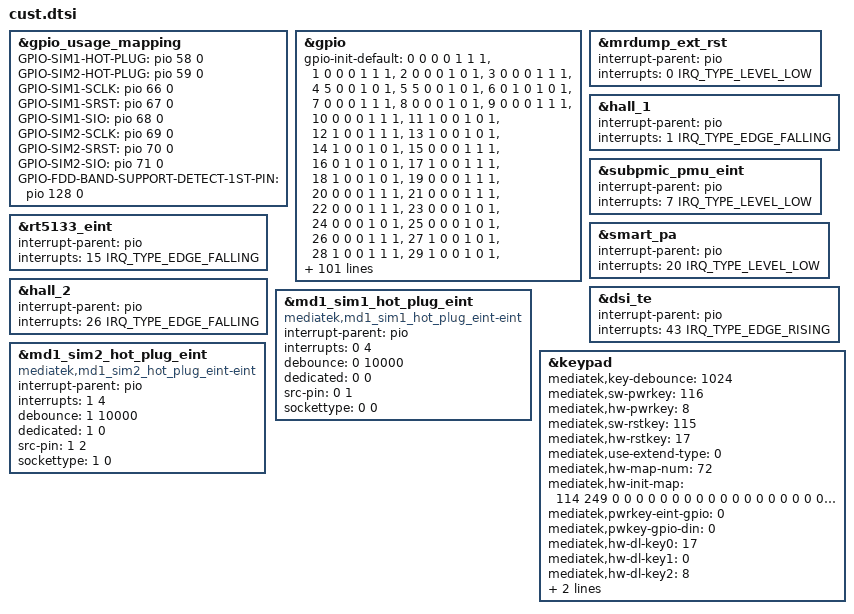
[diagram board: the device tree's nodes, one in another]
/*
 * Generated by MTK SP DrvGen Version: 3.5.160809 for MT6897.
 * 2026-04-27 19:14:05
 * Do Not Modify The File.
 * Copyright Mediatek Inc. (c) 2016.
*/

/*************************
 * ADC DTSI File
*************************/



/*************************
 * CLK_BUF DTSI File
*************************/



/*************************
 * I2C DTSI File
*************************/



/*************************
 * GPIO DTSI File
*************************/

&gpio_usage_mapping {
	GPIO-SIM1-HOT-PLUG = <&pio 58 0>;
	GPIO-SIM2-HOT-PLUG = <&pio 59 0>;
	GPIO-SIM1-SCLK = <&pio 66 0>;
	GPIO-SIM1-SRST = <&pio 67 0>;
	GPIO-SIM1-SIO = <&pio 68 0>;
	GPIO-SIM2-SCLK = <&pio 69 0>;
	GPIO-SIM2-SRST = <&pio 70 0>;
	GPIO-SIM2-SIO = <&pio 71 0>;
	GPIO-FDD-BAND-SUPPORT-DETECT-1ST-PIN = <&pio 128 0>;
};

&gpio{
	gpio-init-default = <0 0 0 0 1 1 1>,
		<1 0 0 0 1 1 1>,
		<2 0 0 0 1 0 1>,
		<3 0 0 0 1 1 1>,
		<4 5 0 0 1 0 1>,
		<5 5 0 0 1 0 1>,
		<6 0 1 0 1 0 1>,
		<7 0 0 0 1 1 1>,
		<8 0 0 0 1 0 1>,
		<9 0 0 0 1 1 1>,
		<10 0 0 0 1 1 1>,
		<11 1 0 0 1 0 1>,
		<12 1 0 0 1 1 1>,
		<13 1 0 0 1 0 1>,
		<14 1 0 0 1 0 1>,
		<15 0 0 0 1 1 1>,
		<16 0 1 0 1 0 1>,
		<17 1 0 0 1 1 1>,
		<18 1 0 0 1 0 1>,
		<19 0 0 0 1 1 1>,
		<20 0 0 0 1 1 1>,
		<21 0 0 0 1 1 1>,
		<22 0 0 0 1 1 1>,
		<23 0 0 0 1 0 1>,
		<24 0 0 0 1 0 1>,
		<25 0 0 0 1 0 1>,
		<26 0 0 0 1 1 1>,
		<27 1 0 0 1 0 1>,
		<28 1 0 0 1 1 1>,
		<29 1 0 0 1 0 1>,
		<30 1 0 0 1 0 1>,
		<31 1 0 0 1 1 1>,
		<32 1 0 0 1 1 1>,
		<33 0 0 0 1 1 1>,
		<34 0 1 0 1 0 1>,
		<36 0 1 0 1 0 1>,
		<37 0 0 0 1 0 1>,
		<38 0 0 0 1 0 1>,
		<39 0 0 0 1 0 1>,
		<40 0 1 0 1 0 0>,
		<41 0 1 0 1 0 1>,
		<42 0 0 0 1 0 0>,
		<43 1 0 0 1 0 1>,
		<44 0 1 0 1 0 1>,
		<45 3 0 0 1 0 1>,
		<46 2 0 0 1 0 1>,
		<47 2 0 0 1 1 1>,
		<48 2 0 0 1 0 1>,
		<49 2 0 0 1 0 1>,
		<50 1 0 0 1 0 1>,
		<51 1 0 0 1 1 1>,
		<52 1 0 0 1 0 1>,
		<53 1 0 0 1 0 1>,
		<54 1 0 0 1 0 1>,
		<55 1 0 0 1 1 1>,
		<56 1 0 0 1 0 1>,
		<57 1 0 0 1 0 1>,
		<58 1 0 0 1 1 1>,
		<59 1 0 0 1 1 1>,
		<60 0 1 0 1 0 1>,
		<61 0 1 0 1 0 1>,
		<62 5 0 0 1 0 1>,
		<63 0 1 0 1 0 0>,
		<64 0 1 0 1 0 1>,
		<65 5 0 0 1 0 1>,
		<66 1 0 0 0 0 1>,
		<67 1 0 0 0 0 1>,
		<68 1 0 0 1 1 1>,
		<69 1 0 0 0 0 1>,
		<70 1 0 0 0 0 1>,
		<71 0 0 0 1 0 1>,
		<72 1 0 0 0 0 1>,
		<73 1 0 0 1 1 1>,
		<74 1 0 0 1 1 1>,
		<75 1 0 0 1 1 1>,
		<76 1 0 0 1 1 1>,
		<77 1 0 0 1 1 1>,
		<78 7 0 0 1 0 1>,
		<79 7 0 0 1 0 1>,
		<80 7 0 0 1 0 1>,
		<81 7 0 0 0 0 1>,
		<82 7 0 0 1 0 1>,
		<83 4 0 0 1 0 1>,
		<84 0 0 0 1 0 0>,
		<85 1 0 0 0 0 1>,
		<86 1 0 0 0 0 1>,
		<87 1 0 0 0 0 1>,
		<88 1 0 0 0 0 1>,
		<89 1 0 0 0 0 1>,
		<90 1 0 0 0 0 1>,
		<91 1 0 0 0 0 1>,
		<92 1 0 0 0 0 1>,
		<93 1 0 0 0 0 1>,
		<94 1 0 0 0 0 1>,
		<95 1 0 0 0 0 1>,
		<96 1 0 0 0 0 1>,
		<97 1 0 0 0 0 1>,
		<98 1 0 0 0 0 1>,
		<99 1 0 0 0 0 1>,
		<100 1 0 0 0 0 1>,
		<101 1 0 0 0 0 1>,
		<102 1 0 0 0 0 1>,
		<103 0 0 0 0 0 1>,
		<104 0 0 0 0 0 1>,
		<105 1 0 0 0 0 0>,
		<106 1 0 0 1 0 0>,
		<107 1 0 0 0 0 0>,
		<108 1 0 0 1 0 0>,
		<109 1 0 0 0 0 0>,
		<110 1 0 0 1 0 0>,
		<111 1 0 0 0 0 0>,
		<112 1 0 0 1 0 0>,
		<113 1 0 0 0 0 0>,
		<114 1 0 0 1 0 0>,
		<115 0 1 0 1 0 1>,
		<116 0 1 0 1 0 1>,
		<117 0 1 0 1 0 1>,
		<118 0 1 0 1 0 1>,
		<119 0 0 0 1 0 1>,
		<120 0 0 0 1 0 1>,
		<121 0 1 0 1 0 1>,
		<122 3 0 0 1 1 1>,
		<123 1 0 0 1 0 1>,
		<124 1 0 0 1 0 1>,
		<125 1 0 0 1 0 1>,
		<126 1 0 0 1 0 1>,
		<127 1 0 0 1 0 1>,
		<128 0 0 0 1 0 1>,
		<129 0 0 0 1 0 1>,
		<130 3 0 0 0 0 1>,
		<131 1 0 0 0 0 1>,
		<132 0 0 0 1 0 1>,
		<133 0 1 0 1 0 1>,
		<134 0 0 0 1 0 1>,
		<135 2 0 0 1 1 1>,
		<136 2 0 0 1 1 1>,
		<137 1 0 0 1 1 1>,
		<138 1 0 0 1 1 1>,
		<139 1 0 0 1 1 0>,
		<140 1 0 0 1 1 0>,
		<141 1 0 0 1 1 1>,
		<142 1 0 0 1 1 1>,
		<143 1 0 0 1 1 1>,
		<144 1 0 0 1 1 1>,
		<145 1 0 0 1 1 1>,
		<146 1 0 0 1 1 1>,
		<147 1 0 0 1 1 1>,
		<148 1 0 0 1 1 1>,
		<149 1 0 0 1 1 1>,
		<150 1 0 0 1 1 1>,
		<151 1 0 0 1 1 1>,
		<152 1 0 0 1 1 1>,
		<153 1 0 0 1 1 1>,
		<154 1 0 0 1 1 1>,
		<155 1 0 0 1 1 1>,
		<156 1 0 0 1 1 1>,
		<157 1 0 0 1 1 1>,
		<158 1 0 0 1 1 1>,
		<159 0 0 0 0 0 1>,
		<160 0 0 0 0 0 1>,
		<161 1 0 0 1 1 1>,
		<162 1 0 0 1 1 1>,
		<163 1 0 0 1 1 1>,
		<164 1 0 0 1 1 1>,
		<165 0 0 0 0 0 1>,
		<166 0 0 0 0 0 1>,
		<167 1 0 0 1 1 1>,
		<168 1 0 0 1 1 1>,
		<169 7 0 0 0 0 1>,
		<170 7 0 0 1 1 1>,
		<171 1 0 0 1 1 1>,
		<172 1 0 0 1 1 1>,
		<173 0 0 0 1 0 0>,
		<174 0 1 0 1 0 1>,
		<175 1 0 0 1 0 1>,
		<176 0 0 0 1 0 0>,
		<177 1 0 0 1 0 1>,
		<178 0 0 0 1 0 0>,
		<179 0 0 0 1 0 0>,
		<180 2 0 0 1 1 1>,
		<181 2 0 0 0 0 1>,
		<182 0 0 0 1 0 0>,
		<183 0 0 0 1 0 1>,
		<184 0 0 0 1 0 1>,
		<185 0 0 0 1 0 0>,
		<186 0 0 0 1 0 0>,
		<187 0 0 0 1 0 0>,
		<188 0 0 0 1 0 0>,
		<189 0 0 0 1 0 1>,
		<190 1 0 0 1 0 1>,
		<191 1 0 0 1 0 1>,
		<192 0 0 0 1 0 1>,
		<193 0 0 0 1 0 1>,
		<194 0 0 0 1 0 1>,
		<195 0 0 0 1 0 1>,
		<196 0 0 0 1 0 1>,
		<197 0 0 0 1 0 1>,
		<198 0 0 0 1 0 1>,
		<199 0 0 0 1 0 1>,
		<200 0 0 0 1 0 1>,
		<201 0 0 0 1 0 1>,
		<202 0 0 0 1 0 1>,
		<203 1 0 0 1 0 1>,
		<204 1 0 0 1 0 1>,
		<205 1 0 0 1 0 1>,
		<206 1 0 0 1 0 1>,
		<207 1 0 0 0 0 1>,
		<208 1 0 0 1 1 1>,
		<209 1 0 0 1 0 1>,
		<210 1 0 0 1 0 1>,
		<211 1 0 0 1 0 1>,
		<212 1 0 0 1 0 1>,
		<213 1 0 0 0 0 1>,
		<214 1 0 0 0 0 1>,
		<215 1 0 0 0 0 1>,
		<216 1 0 0 0 0 1>,
		<217 1 0 0 1 0 1>,
		<218 1 0 0 0 0 1>,
		<219 1 0 0 0 0 1>,
		<220 1 0 0 0 0 1>,
		<221 1 0 0 0 0 1>,
		<222 1 0 0 0 0 1>,
		<223 1 0 0 0 0 1>,
		<224 1 0 0 0 0 1>,
		<225 1 0 0 0 0 1>,
		<226 1 0 0 0 0 1>,
		<227 1 0 0 0 0 1>,
		<228 1 0 0 0 0 1>,
		<229 1 0 0 1 0 1>,
		<230 1 0 0 1 0 1>,
		<231 1 0 0 1 0 1>;
};


/*************************
 * EINT DTSI File
*************************/

#include <dt-bindings/interrupt-controller/irq.h>
#include <dt-bindings/interrupt-controller/arm-gic.h>

&mrdump_ext_rst {
	interrupt-parent = <&pio>;
	interrupts = <0 IRQ_TYPE_LEVEL_LOW>;
	status = "okay";
};

&hall_1 {
	interrupt-parent = <&pio>;
	interrupts = <1 IRQ_TYPE_EDGE_FALLING>;
	status = "okay";
};

&subpmic_pmu_eint {
	interrupt-parent = <&pio>;
	interrupts = <7 IRQ_TYPE_LEVEL_LOW>;
	status = "okay";
};

&rt5133_eint {
	interrupt-parent = <&pio>;
	interrupts = <15 IRQ_TYPE_EDGE_FALLING>;
	status = "okay";
};

&smart_pa {
	interrupt-parent = <&pio>;
	interrupts = <20 IRQ_TYPE_LEVEL_LOW>;
	status = "okay";
};

&hall_2 {
	interrupt-parent = <&pio>;
	interrupts = <26 IRQ_TYPE_EDGE_FALLING>;
	status = "okay";
};

&dsi_te {
	interrupt-parent = <&pio>;
	interrupts = <43 IRQ_TYPE_EDGE_RISING>;
	status = "okay";
};



/*************************
 * MD1_EINT DTSI File
*************************/

&md1_sim1_hot_plug_eint {
	compatible = "mediatek,md1_sim1_hot_plug_eint-eint";
	interrupt-parent = <&pio>;
	interrupts = <0 4>;
	debounce = <0 10000>;
	dedicated = <0 0>;
	src-pin = <0 1>;
	sockettype = <0 0>;
	status = "okay";
};

&md1_sim2_hot_plug_eint {
	compatible = "mediatek,md1_sim2_hot_plug_eint-eint";
	interrupt-parent = <&pio>;
	interrupts = <1 4>;
	debounce = <1 10000>;
	dedicated = <1 0>;
	src-pin = <1 2>;
	sockettype = <1 0>;
	status = "okay";
};



/*************************
 * PMIC DTSI File
*************************/



/*************************
 * POWER DTSI File
*************************/



/*************************
 * KPD DTSI File
*************************/

&keypad {
	mediatek,key-debounce = <1024>;
	mediatek,sw-pwrkey = <116>;
	mediatek,hw-pwrkey = <8>;
	mediatek,sw-rstkey  = <115>;
	mediatek,hw-rstkey = <17>;
	mediatek,use-extend-type = <0>;
	/*HW Keycode [0~71] -> Linux Keycode*/
	mediatek,hw-map-num = <72>;
	mediatek,hw-init-map = <114 249 0 0 0 0 0 0 0 0 0 0 0 0 0 0 0 0 0 0 0 0 0 0 0 0 0 0 0 0 0 0 0 0 0 0 0 0 0 0 0 0 0 0 0 0 0 0 0 0 0 0 0 0 0 0 0 0 0 0 0 0 0 0 0 0 0 0 0 0 0 0 >;
	mediatek,pwrkey-eint-gpio = <0>;
	mediatek,pwkey-gpio-din  = <0>;
	mediatek,hw-dl-key0 = <17>;
	mediatek,hw-dl-key1 = <0>;
	mediatek,hw-dl-key2 = <8>;
	mediatek,hw-recovery-key = <17>;
	mediatek,hw-factory-key = <0>;
	status = "okay";
};


